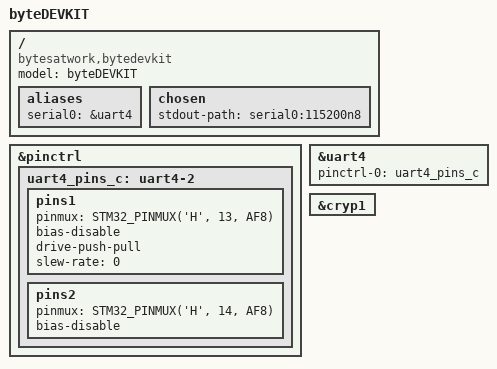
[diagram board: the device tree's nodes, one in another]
// SPDX-License-Identifier: (GPL-2.0+ OR BSD-3-Clause)
/*
 * Copyright (C) 2022 bytesatwork AG - https://www.bytesatwork.io
 * Author: Markus Kappeler <markus.kappeler@bytesatwork.ch>.
 */

/dts-v1/;

#include "stm32mp157.dtsi"
#include "stm32mp15xc.dtsi"
#include "stm32mp15-pinctrl.dtsi"
#include "stm32mp15xxac-pinctrl.dtsi"
#include "stm32mp15xx-byteengine.dtsi"
#include <dt-bindings/soc/st,stm32-etzpc.h>

/ {
	model = "byteDEVKIT";
	compatible = "bytesatwork,bytedevkit", "bytesatwork,byteengine-stm32mp1", "st,stm32mp157";

	aliases {
		serial0 = &uart4;
	};

	chosen {
		stdout-path = "serial0:115200n8";
	};
};

&pinctrl {
	uart4_pins_c: uart4-2 {
		pins1 {
			pinmux = <STM32_PINMUX('H', 13, AF8)>; /* UART4_TX */
			bias-disable;
			drive-push-pull;
			slew-rate = <0>;
		};

		pins2 {
			pinmux = <STM32_PINMUX('H', 14, AF8)>; /* UART4_RX */
			bias-disable;
		};
	};
};

&uart4 {
	pinctrl-names = "default" ;
	pinctrl-0 = <&uart4_pins_c>;
	status = "okay";
};

&cryp1 {
	status = "okay";
};
